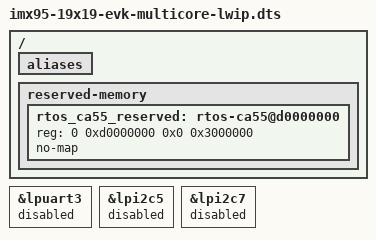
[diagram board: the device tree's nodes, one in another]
// SPDX-License-Identifier: (GPL-2.0 OR MIT)
/*
 * Copyright 2026 NXP
 */

/dts-v1/;
#include "imx95-19x19-evk.dts"
#include "imx95-rproc-ca55.dtsi"

/ {
	aliases {
		/delete-property/ ethernet0;
		/delete-property/ ethernet1;
	};

	reserved-memory {
		#address-cells = <2>;
		#size-cells = <2>;
		ranges;

		/*
		 * Reserve up to 3 x 16MB for three possible FreeRTOS instances running on
		 * Cortex-A Cores when booting Linux.
		 */
		rtos_ca55_reserved: rtos-ca55@d0000000 {
			reg = <0 0xd0000000 0x0 0x3000000>;
			no-map;
		};
	};
};

/delete-node/ &netcmix_blk_ctrl;
/delete-node/ &netc_blk_ctrl;
/delete-node/ &pinctrl_enetc0;
/delete-node/ &pinctrl_emdio;

&lpuart3 {
	status = "disabled";
};

&lpi2c5 {
	status = "disabled";
};

&lpi2c7 {
	status = "disabled";
};
